# STM32G031C4T6 register map
File version: 1.0
Registers are 32-bit, access not given, reset 0x0 unless marked. A register's access mark holds for its fields unless they carry their own. Offsets are from the block's base; [hi:lo] are bit positions; {n}, {i} and the like mark numbered series.

## LPUART1
Base 0x40008000
Same registers: LPUART2 0x40008400
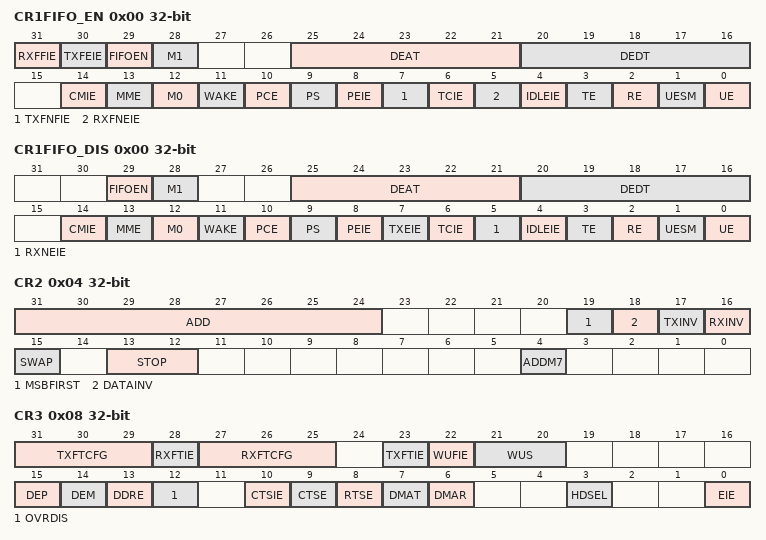
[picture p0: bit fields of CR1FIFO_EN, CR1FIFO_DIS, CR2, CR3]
0x00 CR1FIFO_EN
  [31] RXFFIE, [30] TXFEIE, [29] FIFOEN, [28] M1, [25:21] DEAT, [20:16] DEDT, [14] CMIE, [13] MME, [12] M0, [11] WAKE, [10] PCE, [9] PS, [8] PEIE, [7] TXFNFIE, [6] TCIE, [5] RXFNEIE, [4] IDLEIE, [3] TE, [2] RE, [1] UESM, [0] UE
0x00 CR1FIFO_DIS
  [29] FIFOEN, [28] M1, [25:21] DEAT, [20:16] DEDT, [14] CMIE, [13] MME, [12] M0, [11] WAKE, [10] PCE, [9] PS, [8] PEIE, [7] TXEIE, [6] TCIE, [5] RXNEIE, [4] IDLEIE, [3] TE, [2] RE, [1] UESM, [0] UE
0x04 CR2
  [31:24] ADD, [19] MSBFIRST, [18] DATAINV, [17] TXINV, [16] RXINV, [15] SWAP, [13:12] STOP, [4] ADDM7
0x08 CR3
  [31:29] TXFTCFG, [28] RXFTIE, [27:25] RXFTCFG, [23] TXFTIE, [22] WUFIE, [21:20] WUS, [15] DEP, [14] DEM, [13] DDRE, [12] OVRDIS, [10] CTSIE, [9] CTSE, [8] RTSE, [7] DMAT, [6] DMAR, [3] HDSEL, [0] EIE
0x0C BRR
  [19:0] BRR
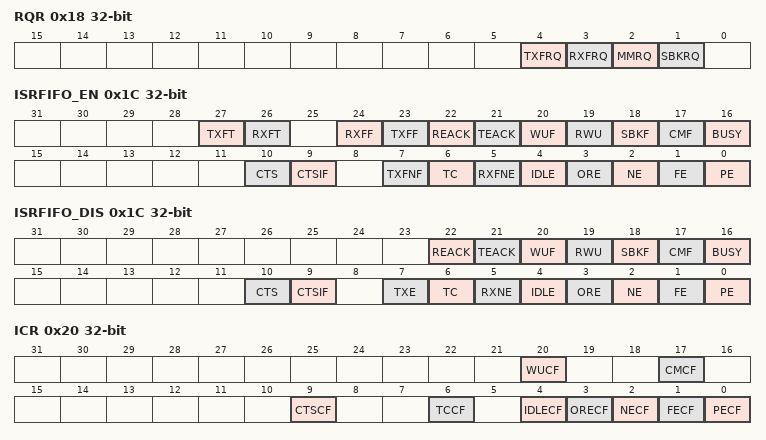
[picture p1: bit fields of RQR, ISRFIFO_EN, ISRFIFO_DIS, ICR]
0x18 RQR
  [4] TXFRQ, [3] RXFRQ, [2] MMRQ, [1] SBKRQ
0x1C ISRFIFO_EN
  [27] TXFT, [26] RXFT, [24] RXFF, [23] TXFF, [22] REACK, [21] TEACK, [20] WUF, [19] RWU, [18] SBKF, [17] CMF, [16] BUSY, [10] CTS, [9] CTSIF, [7] TXFNF, [6] TC, [5] RXFNE, [4] IDLE, [3] ORE, [2] NE, [1] FE, [0] PE
0x1C ISRFIFO_DIS
  [22] REACK, [21] TEACK, [20] WUF, [19] RWU, [18] SBKF, [17] CMF, [16] BUSY, [10] CTS, [9] CTSIF, [7] TXE, [6] TC, [5] RXNE, [4] IDLE, [3] ORE, [2] NE, [1] FE, [0] PE
0x20 ICR
  [20] WUCF, [17] CMCF, [9] CTSCF, [6] TCCF, [4] IDLECF, [3] ORECF, [2] NECF, [1] FECF, [0] PECF
0x24 RDR
  [8:0] RDR
0x28 TDR
  [8:0] TDR
0x2C PRESC
  [3:0] PRESCALER

## UCPD1
Base 0x4000A000
Same registers: UCPD2 0x4000A400
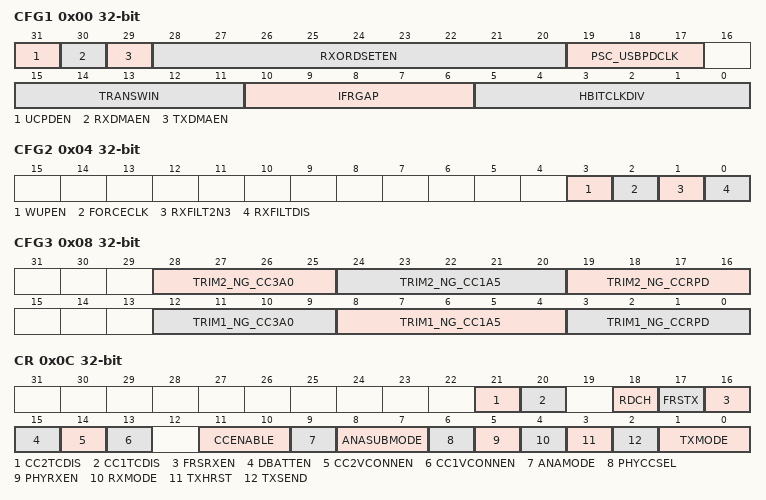
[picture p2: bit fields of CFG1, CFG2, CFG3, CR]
0x00 CFG1
  [31] UCPDEN, [30] RXDMAEN, [29] TXDMAEN, [28:20] RXORDSETEN, [19:17] PSC_USBPDCLK, [15:11] TRANSWIN, [10:6] IFRGAP, [5:0] HBITCLKDIV
0x04 CFG2
  [3] WUPEN, [2] FORCECLK, [1] RXFILT2N3, [0] RXFILTDIS
0x08 CFG3
  [28:25] TRIM2_NG_CC3A0, [24:20] TRIM2_NG_CC1A5, [19:16] TRIM2_NG_CCRPD, [12:9] TRIM1_NG_CC3A0, [8:4] TRIM1_NG_CC1A5, [3:0] TRIM1_NG_CCRPD
0x0C CR
  [21] CC2TCDIS, [20] CC1TCDIS, [18] RDCH, [17] FRSTX, [16] FRSRXEN, [15] DBATTEN, [14] CC2VCONNEN, [13] CC1VCONNEN, [11:10] CCENABLE, [9] ANAMODE, [8:7] ANASUBMODE, [6] PHYCCSEL, [5] PHYRXEN, [4] RXMODE, [3] TXHRST, [2] TXSEND, [1:0] TXMODE
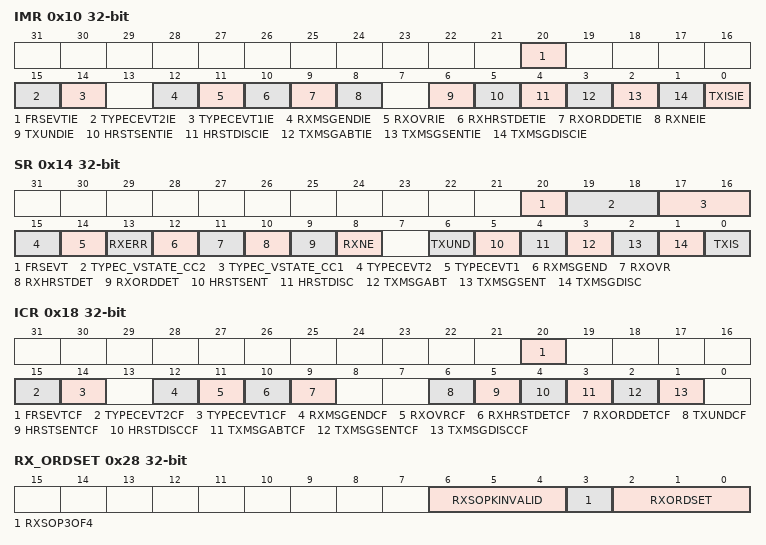
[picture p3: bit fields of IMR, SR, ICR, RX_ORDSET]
0x10 IMR
  [20] FRSEVTIE, [15] TYPECEVT2IE, [14] TYPECEVT1IE, [12] RXMSGENDIE, [11] RXOVRIE, [10] RXHRSTDETIE, [9] RXORDDETIE, [8] RXNEIE, [6] TXUNDIE, [5] HRSTSENTIE, [4] HRSTDISCIE, [3] TXMSGABTIE, [2] TXMSGSENTIE, [1] TXMSGDISCIE, [0] TXISIE
0x14 SR
  [20] FRSEVT, [19:18] TYPEC_VSTATE_CC2, [17:16] TYPEC_VSTATE_CC1, [15] TYPECEVT2, [14] TYPECEVT1, [13] RXERR, [12] RXMSGEND, [11] RXOVR, [10] RXHRSTDET, [9] RXORDDET, [8] RXNE, [6] TXUND, [5] HRSTSENT, [4] HRSTDISC, [3] TXMSGABT, [2] TXMSGSENT, [1] TXMSGDISC, [0] TXIS
0x18 ICR
  [20] FRSEVTCF, [15] TYPECEVT2CF, [14] TYPECEVT1CF, [12] RXMSGENDCF, [11] RXOVRCF, [10] RXHRSTDETCF, [9] RXORDDETCF, [6] TXUNDCF, [5] HRSTSENTCF, [4] HRSTDISCCF, [3] TXMSGABTCF, [2] TXMSGSENTCF, [1] TXMSGDISCCF
0x1C TX_ORDSET
  [19:0] TXORDSET
0x20 TX_PAYSZ
  [9:0] TXPAYSZ
0x24 TXDR
  [7:0] TXDATA
0x28 RX_ORDSET
  [6:4] RXSOPKINVALID, [3] RXSOP3OF4, [2:0] RXORDSET
0x2C RX_PAYSZ
  [9:0] RXPAYSZ
0x30 RXDR
  [7:0] RXDATA
0x34 RX_ORDEXT1
  [19:0] RXSOPX1
0x38 RX_ORDEXT2
  [19:0] RXSOPX2

## TAMP
Base 0x4000B000
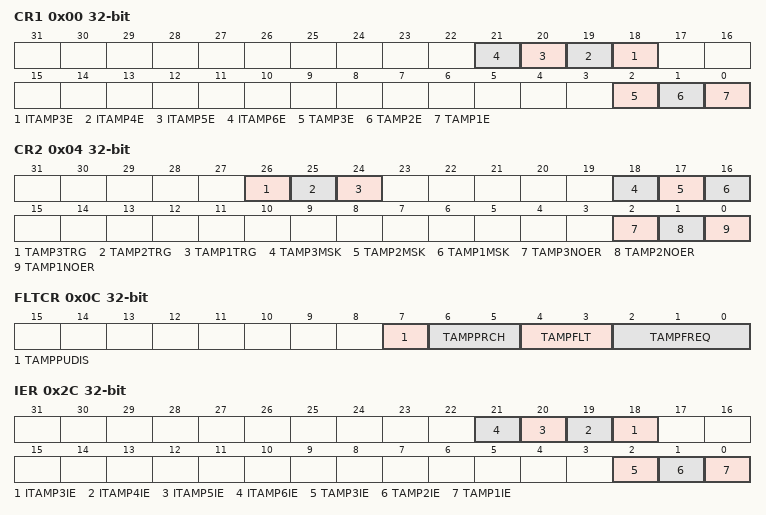
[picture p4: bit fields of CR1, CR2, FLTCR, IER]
0x00 CR1
  [n+15] ITAMP{n}E (n=3..6), [2] TAMP3E, [1] TAMP2E, [0] TAMP1E
0x04 CR2
  [26] TAMP3TRG, [25] TAMP2TRG, [24] TAMP1TRG, [18] TAMP3MSK, [17] TAMP2MSK, [16] TAMP1MSK, [2] TAMP3NOER, [1] TAMP2NOER, [0] TAMP1NOER
0x0C FLTCR
  [7] TAMPPUDIS, [6:5] TAMPPRCH, [4:3] TAMPFLT, [2:0] TAMPFREQ
0x2C IER
  [n+15] ITAMP{n}IE (n=3..6), [2] TAMP3IE, [1] TAMP2IE, [0] TAMP1IE
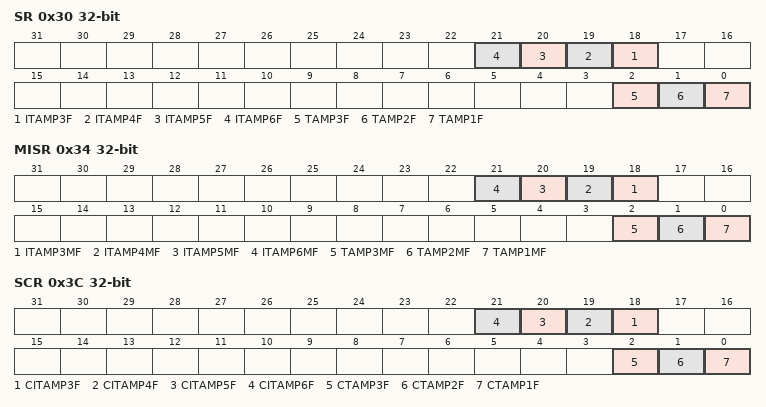
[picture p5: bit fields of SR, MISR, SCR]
0x30 SR
  [n+15] ITAMP{n}F (n=3..6), [2] TAMP3F, [1] TAMP2F, [0] TAMP1F
0x34 MISR
  [n+15] ITAMP{n}MF (n=3..6), [2] TAMP3MF, [1] TAMP2MF, [0] TAMP1MF
0x3C SCR
  [n+15] CITAMP{n}F (n=3..6), [2] CTAMP3F, [1] CTAMP2F, [0] CTAMP1F
{0x100+4i} BKP{i}R (i=0..4)
  [31:0] BKP
